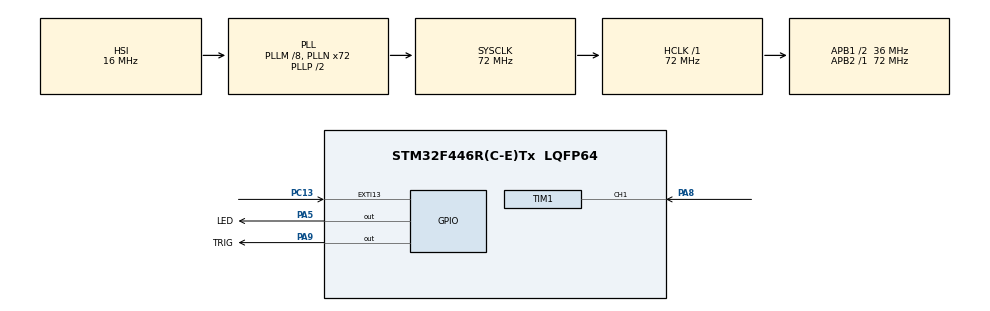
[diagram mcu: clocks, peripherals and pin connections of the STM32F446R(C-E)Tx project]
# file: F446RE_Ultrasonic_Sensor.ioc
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Mcu.Family=STM32F4
Mcu.Name=STM32F446R(C-E)Tx
Mcu.Package=LQFP64
NVIC.EXTI15_10_IRQn=true\:0\:0\:false\:false\:true\:true\:true\:true
NVIC.PriorityGroup=NVIC_PRIORITYGROUP_0
NVIC.TIM1_CC_IRQn=true\:0\:0\:false\:false\:true\:true\:true\:true
NVIC.TIM6_DAC_IRQn=true\:0\:0\:false\:false\:true\:true\:true\:true
PA13.Mode=Serial_Wire
PA13.Signal=SYS_JTMS-SWDIO
PA14.Mode=Serial_Wire
PA14.Signal=SYS_JTCK-SWCLK
PA5.GPIO_Label=LED
PA5.Signal=GPIO_Output
PA8.Signal=S_TIM1_CH1
PA9.GPIO_Label=TRIG
PA9.Signal=GPIO_Output
PC13.Signal=GPXTI13
PH0-OSC_IN.Mode=HSE-External-Oscillator
PH0-OSC_IN.Signal=RCC_OSC_IN
PH1-OSC_OUT.Mode=HSE-External-Oscillator
PH1-OSC_OUT.Signal=RCC_OSC_OUT
ProjectManager.HeapSize=0x200
ProjectManager.StackSize=0x400
ProjectManager.TargetToolchain=STM32CubeIDE
RCC.48MHZClocksFreq_Value=84000000
RCC.AHBFreq_Value=72000000
RCC.APB1CLKDivider=RCC_HCLK_DIV2
RCC.APB1Freq_Value=36000000
RCC.APB1TimFreq_Value=72000000
RCC.APB2Freq_Value=72000000
RCC.APB2TimFreq_Value=72000000
RCC.CortexFreq_Value=72000000
RCC.FLatency-AdvancedSettings=FLASH_LATENCY_2
RCC.HCLKFreq_Value=72000000
RCC.HSE_VALUE=8000000
RCC.HSI_VALUE=16000000
RCC.PLLM=8
RCC.PLLN=72
RCC.SYSCLKFreq_VALUE=72000000
RCC.SYSCLKSource=RCC_SYSCLKSOURCE_PLLCLK
RCC.USBFreq_Value=72000000
RCC.VCOOutputFreq_Value=144000000
SH.S_TIM1_CH1.0=TIM1_CH1,Input_Capture1_from_TI1
TIM1.Channel-Input_Capture1_from_TI1=TIM_CHANNEL_1
TIM1.Prescaler=72-1
TIM6.Period=10-1
TIM6.Prescaler=72-1
VP_TIM1_VS_ClockSourceINT.Mode=Internal
VP_TIM6_VS_ClockSourceINT.Mode=Enable_Timer
board=NUCLEO-F446RE

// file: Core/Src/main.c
/* USER CODE BEGIN Header */
/**
  ******************************************************************************
  * @file           : main.c
  * @brief          : Main program body
  ******************************************************************************
  * @attention
  *
  * Copyright (c) 2024 STMicroelectronics.
  * All rights reserved.
  *
  * This software is licensed under terms that can be found in the LICENSE file
  * in the root directory of this software component.
  * If no LICENSE file comes with this software, it is provided AS-IS.
  *
  ******************************************************************************
  */
/* USER CODE END Header */
#include "main.h"

TIM_HandleTypeDef htim1;
TIM_HandleTypeDef htim6;

void SystemClock_Config(void);
static void MX_GPIO_Init(void);
static void MX_TIM1_Init(void);
static void MX_TIM6_Init(void);

/* USER CODE BEGIN 0 */
volatile uint32_t counter = 0;
uint8_t flag = 0;
void HAL_TIM_PeriodElapsedCallback(TIM_HandleTypeDef *htim)
{
	if(htim->Instance == TIM6)
	{
		counter++;
		if(counter == 100000)
		{
			HAL_GPIO_TogglePin(LED_GPIO_Port, LED_Pin);
			counter = 0;
		}
	}
}

//void delay_us(uint32_t us)
//{
//
//	if(counter >= us)
//	{
//		counter = 0;
//	}
//}
//
//void HCSR04_Pulse( void )
//{
//	HAL_GPIO_WritePin(LED_GPIO_Port	, LED_Pin, 1);
//	delay_us(10000000);
//	HAL_GPIO_WritePin(LED_GPIO_Port	, LED_Pin, 0);
//	delay_us(10000000);
//}
/* USER CODE END 0 */

int main(void)
{

  /* MCU Configuration--------------------------------------------------------*/

  /* Reset of all peripherals, Initializes the Flash interface and the Systick. */
  HAL_Init();

  /* Configure the system clock */
  SystemClock_Config();

  /* Initialize all configured peripherals */
  MX_GPIO_Init();
  MX_TIM1_Init();
  MX_TIM6_Init();
  /* USER CODE BEGIN 2 */
  HAL_TIM_Base_Start_IT(&htim6);
  /* USER CODE END 2 */

  /* Infinite loop */
  /* USER CODE BEGIN WHILE */
  while (1)
  {
	 // HCSR04_Pulse();
    /* USER CODE END WHILE */

  }
}

void SystemClock_Config(void)
{
  RCC_OscInitTypeDef RCC_OscInitStruct = {0};
  RCC_ClkInitTypeDef RCC_ClkInitStruct = {0};

  /** Configure the main internal regulator output voltage
  */
  __HAL_RCC_PWR_CLK_ENABLE();
  __HAL_PWR_VOLTAGESCALING_CONFIG(PWR_REGULATOR_VOLTAGE_SCALE3);

  /** Initializes the RCC Oscillators according to the specified parameters
  * in the RCC_OscInitTypeDef structure.
  */
  RCC_OscInitStruct.OscillatorType = RCC_OSCILLATORTYPE_HSI;
  RCC_OscInitStruct.HSIState = RCC_HSI_ON;
  RCC_OscInitStruct.HSICalibrationValue = RCC_HSICALIBRATION_DEFAULT;
  RCC_OscInitStruct.PLL.PLLState = RCC_PLL_ON;
  RCC_OscInitStruct.PLL.PLLSource = RCC_PLLSOURCE_HSI;
  RCC_OscInitStruct.PLL.PLLM = 8;
  RCC_OscInitStruct.PLL.PLLN = 72;
  RCC_OscInitStruct.PLL.PLLP = RCC_PLLP_DIV2;
  RCC_OscInitStruct.PLL.PLLQ = 2;
  RCC_OscInitStruct.PLL.PLLR = 2;
  if (HAL_RCC_OscConfig(&RCC_OscInitStruct) != HAL_OK)
  {
    Error_Handler();
  }

  /** Initializes the CPU, AHB and APB buses clocks
  */
  RCC_ClkInitStruct.ClockType = RCC_CLOCKTYPE_HCLK|RCC_CLOCKTYPE_SYSCLK
                              |RCC_CLOCKTYPE_PCLK1|RCC_CLOCKTYPE_PCLK2;
  RCC_ClkInitStruct.SYSCLKSource = RCC_SYSCLKSOURCE_PLLCLK;
  RCC_ClkInitStruct.AHBCLKDivider = RCC_SYSCLK_DIV1;
  RCC_ClkInitStruct.APB1CLKDivider = RCC_HCLK_DIV2;
  RCC_ClkInitStruct.APB2CLKDivider = RCC_HCLK_DIV1;

  if (HAL_RCC_ClockConfig(&RCC_ClkInitStruct, FLASH_LATENCY_2) != HAL_OK)
  {
    Error_Handler();
  }
}

static void MX_TIM1_Init(void)
{

  TIM_ClockConfigTypeDef sClockSourceConfig = {0};
  TIM_MasterConfigTypeDef sMasterConfig = {0};
  TIM_IC_InitTypeDef sConfigIC = {0};

  htim1.Instance = TIM1;
  htim1.Init.Prescaler = 72-1;
  htim1.Init.CounterMode = TIM_COUNTERMODE_UP;
  htim1.Init.Period = 65535;
  htim1.Init.ClockDivision = TIM_CLOCKDIVISION_DIV1;
  htim1.Init.RepetitionCounter = 0;
  htim1.Init.AutoReloadPreload = TIM_AUTORELOAD_PRELOAD_DISABLE;
  if (HAL_TIM_Base_Init(&htim1) != HAL_OK)
  {
    Error_Handler();
  }
  sClockSourceConfig.ClockSource = TIM_CLOCKSOURCE_INTERNAL;
  if (HAL_TIM_ConfigClockSource(&htim1, &sClockSourceConfig) != HAL_OK)
  {
    Error_Handler();
  }
  if (HAL_TIM_IC_Init(&htim1) != HAL_OK)
  {
    Error_Handler();
  }
  sMasterConfig.MasterOutputTrigger = TIM_TRGO_RESET;
  sMasterConfig.MasterSlaveMode = TIM_MASTERSLAVEMODE_DISABLE;
  if (HAL_TIMEx_MasterConfigSynchronization(&htim1, &sMasterConfig) != HAL_OK)
  {
    Error_Handler();
  }
  sConfigIC.ICPolarity = TIM_INPUTCHANNELPOLARITY_RISING;
  sConfigIC.ICSelection = TIM_ICSELECTION_DIRECTTI;
  sConfigIC.ICPrescaler = TIM_ICPSC_DIV1;
  sConfigIC.ICFilter = 0;
  if (HAL_TIM_IC_ConfigChannel(&htim1, &sConfigIC, TIM_CHANNEL_1) != HAL_OK)
  {
    Error_Handler();
  }

}

static void MX_TIM6_Init(void)
{

  TIM_MasterConfigTypeDef sMasterConfig = {0};

  htim6.Instance = TIM6;
  htim6.Init.Prescaler = 72-1;
  htim6.Init.CounterMode = TIM_COUNTERMODE_UP;
  htim6.Init.Period = 1-1;
  htim6.Init.AutoReloadPreload = TIM_AUTORELOAD_PRELOAD_DISABLE;
  if (HAL_TIM_Base_Init(&htim6) != HAL_OK)
  {
    Error_Handler();
  }
  sMasterConfig.MasterOutputTrigger = TIM_TRGO_RESET;
  sMasterConfig.MasterSlaveMode = TIM_MASTERSLAVEMODE_DISABLE;
  if (HAL_TIMEx_MasterConfigSynchronization(&htim6, &sMasterConfig) != HAL_OK)
  {
    Error_Handler();
  }

}

static void MX_GPIO_Init(void)
{
  GPIO_InitTypeDef GPIO_InitStruct = {0};

  /* GPIO Ports Clock Enable */
  __HAL_RCC_GPIOC_CLK_ENABLE();
  __HAL_RCC_GPIOH_CLK_ENABLE();
  __HAL_RCC_GPIOA_CLK_ENABLE();

  /*Configure GPIO pin Output Level */
  HAL_GPIO_WritePin(GPIOA, LED_Pin|TRIG_Pin, GPIO_PIN_RESET);

  /*Configure GPIO pin : PC13 */
  GPIO_InitStruct.Pin = GPIO_PIN_13;
  GPIO_InitStruct.Mode = GPIO_MODE_IT_RISING;
  GPIO_InitStruct.Pull = GPIO_NOPULL;
  HAL_GPIO_Init(GPIOC, &GPIO_InitStruct);

  /*Configure GPIO pins : LED_Pin TRIG_Pin */
  GPIO_InitStruct.Pin = LED_Pin|TRIG_Pin;
  GPIO_InitStruct.Mode = GPIO_MODE_OUTPUT_PP;
  GPIO_InitStruct.Pull = GPIO_NOPULL;
  GPIO_InitStruct.Speed = GPIO_SPEED_FREQ_LOW;
  HAL_GPIO_Init(GPIOA, &GPIO_InitStruct);

  /* EXTI interrupt init*/
  HAL_NVIC_SetPriority(EXTI15_10_IRQn, 0, 0);
  HAL_NVIC_EnableIRQ(EXTI15_10_IRQn);

}

void Error_Handler(void)
{
  __disable_irq();
  while (1)
  {
  }
}
